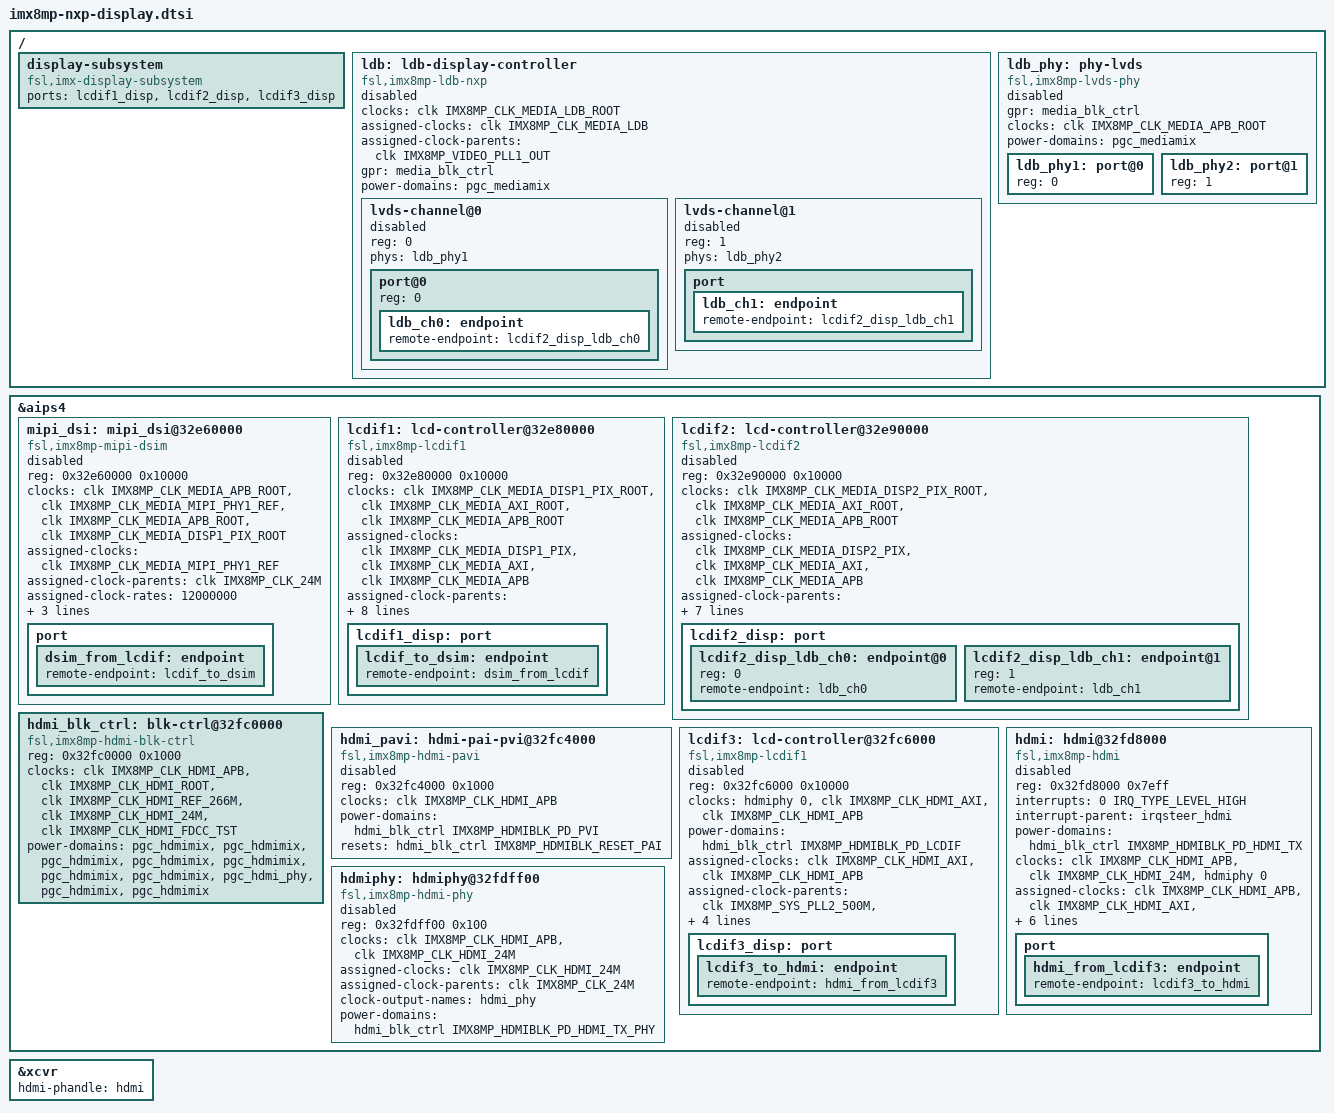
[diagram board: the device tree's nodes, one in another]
// SPDX-License-Identifier: (GPL-2.0+ OR MIT)
/*
 * Copyright 2025 NXP
 */

/delete-node/ &hdmi_blk_ctrl;
/delete-node/ &hdmi_pvi;
/delete-node/ &hdmi_tx;
/delete-node/ &hdmi_tx_phy;
/delete-node/ &lcdif1;
/delete-node/ &lcdif2;
/delete-node/ &lcdif3;
/delete-node/ &lvds_bridge;
/delete-node/ &mipi_dsi;

/ {
	display-subsystem {
		compatible = "fsl,imx-display-subsystem";
		ports = <&lcdif1_disp>, <&lcdif2_disp>, <&lcdif3_disp>;
	};

	ldb: ldb-display-controller {
		#address-cells = <1>;
		#size-cells = <0>;
		compatible = "fsl,imx8mp-ldb-nxp";
		clocks = <&clk IMX8MP_CLK_MEDIA_LDB_ROOT>;
		clock-names = "ldb";
		assigned-clocks = <&clk IMX8MP_CLK_MEDIA_LDB>;
		assigned-clock-parents = <&clk IMX8MP_VIDEO_PLL1_OUT>;
		gpr = <&media_blk_ctrl>;
		power-domains = <&pgc_mediamix>;
		status = "disabled";

		lvds-channel@0 {
			#address-cells = <1>;
			#size-cells = <0>;
			reg = <0>;
			phys = <&ldb_phy1>;
			phy-names = "ldb_phy";
			status = "disabled";

			port@0 {
				reg = <0>;

				ldb_ch0: endpoint {
					remote-endpoint = <&lcdif2_disp_ldb_ch0>;
				};
			};
		};

		lvds-channel@1 {
			reg = <1>;
			phys = <&ldb_phy2>;
			phy-names = "ldb_phy";
			status = "disabled";

			port {
				ldb_ch1: endpoint {
					remote-endpoint = <&lcdif2_disp_ldb_ch1>;
				};
			};
		};
	};

	ldb_phy: phy-lvds {
		compatible = "fsl,imx8mp-lvds-phy";
		#address-cells = <1>;
		#size-cells = <0>;
		gpr = <&media_blk_ctrl>;
		clocks = <&clk IMX8MP_CLK_MEDIA_APB_ROOT>;
		clock-names = "apb";
		power-domains = <&pgc_mediamix>;
		status = "disabled";

		ldb_phy1: port@0 {
			reg = <0>;
			#phy-cells = <0>;
		};

		ldb_phy2: port@1 {
			reg = <1>;
			#phy-cells = <0>;
		};
	};
};

&aips4 {
	mipi_dsi: mipi_dsi@32e60000 {
		#address-cells = <1>;
		#size-cells = <0>;
		compatible = "fsl,imx8mp-mipi-dsim";
		reg = <0x32e60000 0x10000>;
		clocks = <&clk IMX8MP_CLK_MEDIA_APB_ROOT>,
			 <&clk IMX8MP_CLK_MEDIA_MIPI_PHY1_REF>,
			 <&clk IMX8MP_CLK_MEDIA_APB_ROOT>,
			 <&clk IMX8MP_CLK_MEDIA_DISP1_PIX_ROOT>;
		clock-names = "cfg", "pll-ref", "apb-root", "pixel";
		assigned-clocks = <&clk IMX8MP_CLK_MEDIA_MIPI_PHY1_REF>;
		assigned-clock-parents = <&clk IMX8MP_CLK_24M>;
		assigned-clock-rates = <12000000>;
		interrupts = <GIC_SPI 18 IRQ_TYPE_LEVEL_HIGH>;
		power-domains = <&media_blk_ctrl IMX8MP_MEDIABLK_PD_MIPI_DSI_1>;
		status = "disabled";

		port {
			dsim_from_lcdif: endpoint {
				remote-endpoint = <&lcdif_to_dsim>;
			};
		};
	};

	lcdif1: lcd-controller@32e80000 {
		compatible = "fsl,imx8mp-lcdif1";
		reg = <0x32e80000 0x10000>;
		clocks = <&clk IMX8MP_CLK_MEDIA_DISP1_PIX_ROOT>,
			 <&clk IMX8MP_CLK_MEDIA_AXI_ROOT>,
			 <&clk IMX8MP_CLK_MEDIA_APB_ROOT>;
		clock-names = "pix", "disp-axi", "disp-apb";
		assigned-clocks = <&clk IMX8MP_CLK_MEDIA_DISP1_PIX>,
				  <&clk IMX8MP_CLK_MEDIA_AXI>,
				  <&clk IMX8MP_CLK_MEDIA_APB>;
		assigned-clock-parents = <&clk IMX8MP_VIDEO_PLL1_OUT>,
					 <&clk IMX8MP_SYS_PLL2_1000M>,
					 <&clk IMX8MP_SYS_PLL1_800M>;
		assigned-clock-rates = <0>, <500000000>, <200000000>;
		interrupts = <GIC_SPI 5 IRQ_TYPE_LEVEL_HIGH>;
		blk-ctl = <&media_blk_ctrl>;
		power-domains = <&media_blk_ctrl IMX8MP_MEDIABLK_PD_LCDIF_1>;
		status = "disabled";

		lcdif1_disp: port {
			lcdif_to_dsim: endpoint {
				remote-endpoint = <&dsim_from_lcdif>;
			};
		};
	};

	lcdif2: lcd-controller@32e90000 {
		compatible = "fsl,imx8mp-lcdif2";
		reg = <0x32e90000 0x10000>;
		clocks = <&clk IMX8MP_CLK_MEDIA_DISP2_PIX_ROOT>,
			 <&clk IMX8MP_CLK_MEDIA_AXI_ROOT>,
			 <&clk IMX8MP_CLK_MEDIA_APB_ROOT>;
		clock-names = "pix", "disp-axi", "disp-apb";
		assigned-clocks = <&clk IMX8MP_CLK_MEDIA_DISP2_PIX>,
				  <&clk IMX8MP_CLK_MEDIA_AXI>,
				  <&clk IMX8MP_CLK_MEDIA_APB>;
		assigned-clock-parents = <&clk IMX8MP_VIDEO_PLL1_OUT>,
					 <&clk IMX8MP_SYS_PLL2_1000M>,
					 <&clk IMX8MP_SYS_PLL1_800M>;
		assigned-clock-rates = <0>, <500000000>, <200000000>;
		interrupts = <GIC_SPI 6 IRQ_TYPE_LEVEL_HIGH>;
		power-domains = <&media_blk_ctrl IMX8MP_MEDIABLK_PD_LCDIF_2>;
		status = "disabled";

		lcdif2_disp: port {
			#address-cells = <1>;
			#size-cells = <0>;

			lcdif2_disp_ldb_ch0: endpoint@0 {
				reg = <0>;
				remote-endpoint = <&ldb_ch0>;
			};

			lcdif2_disp_ldb_ch1: endpoint@1 {
				reg = <1>;
				remote-endpoint = <&ldb_ch1>;
			};
		};
	};

	hdmi_blk_ctrl: blk-ctrl@32fc0000 {
		compatible = "fsl,imx8mp-hdmi-blk-ctrl", "syscon";
		reg = <0x32fc0000 0x1000>;
		clocks = <&clk IMX8MP_CLK_HDMI_APB>,
			 <&clk IMX8MP_CLK_HDMI_ROOT>,
			 <&clk IMX8MP_CLK_HDMI_REF_266M>,
			 <&clk IMX8MP_CLK_HDMI_24M>,
			 <&clk IMX8MP_CLK_HDMI_FDCC_TST>;
		clock-names = "apb", "axi", "ref_266m", "ref_24m", "fdcc";
		power-domains = <&pgc_hdmimix>, <&pgc_hdmimix>,
				<&pgc_hdmimix>, <&pgc_hdmimix>,
				<&pgc_hdmimix>, <&pgc_hdmimix>,
				<&pgc_hdmimix>, <&pgc_hdmi_phy>,
				<&pgc_hdmimix>, <&pgc_hdmimix>;
		power-domain-names = "bus", "irqsteer", "lcdif",
				     "pai", "pvi", "trng",
				     "hdmi-tx", "hdmi-tx-phy",
				     "hdcp", "hrv";
		#power-domain-cells = <1>;
		#reset-cells = <1>;
	};

	hdmi_pavi: hdmi-pai-pvi@32fc4000 {
		compatible = "fsl,imx8mp-hdmi-pavi";
		reg = <0x32fc4000 0x1000>;
		clocks = <&clk IMX8MP_CLK_HDMI_APB>;
		power-domains = <&hdmi_blk_ctrl IMX8MP_HDMIBLK_PD_PVI>;
		resets = <&hdmi_blk_ctrl IMX8MP_HDMIBLK_RESET_PAI>;
		reset-names = "pai_rst";
		status = "disabled";
	};

	lcdif3: lcd-controller@32fc6000 {
		compatible = "fsl,imx8mp-lcdif1";
		reg = <0x32fc6000 0x10000>;
		clocks = <&hdmiphy 0>,
				<&clk IMX8MP_CLK_HDMI_AXI>,
				<&clk IMX8MP_CLK_HDMI_APB>;
		clock-names = "pix", "disp-axi", "disp-apb";
		power-domains = <&hdmi_blk_ctrl IMX8MP_HDMIBLK_PD_LCDIF>;
		assigned-clocks =  <&clk IMX8MP_CLK_HDMI_AXI>,
						<&clk IMX8MP_CLK_HDMI_APB>;
		assigned-clock-parents = <&clk IMX8MP_SYS_PLL2_500M>,
					 <&clk IMX8MP_SYS_PLL1_133M>;
		assigned-clock-rates = <500000000>, <133000000>;
		interrupts = <8 IRQ_TYPE_LEVEL_HIGH>;
		interrupt-parent = <&irqsteer_hdmi>;
		status = "disabled";

		lcdif3_disp: port {
			lcdif3_to_hdmi: endpoint {
				remote-endpoint = <&hdmi_from_lcdif3>;
			};
		};
	};

	hdmi: hdmi@32fd8000 {
		compatible = "fsl,imx8mp-hdmi";
		reg = <0x32fd8000 0x7eff>;
		interrupts = <0 IRQ_TYPE_LEVEL_HIGH>;
		interrupt-parent = <&irqsteer_hdmi>;
		power-domains = <&hdmi_blk_ctrl IMX8MP_HDMIBLK_PD_HDMI_TX>;
		clocks = <&clk IMX8MP_CLK_HDMI_APB>,
				<&clk IMX8MP_CLK_HDMI_24M>,
				<&hdmiphy 0>;
		clock-names = "iahb", "isfr", "pix";
		assigned-clocks = <&clk IMX8MP_CLK_HDMI_APB>,
					<&clk IMX8MP_CLK_HDMI_AXI>,
					<&clk IMX8MP_CLK_HDMI_24M>;
		assigned-clock-parents = <&clk IMX8MP_SYS_PLL1_133M>,
					<&clk IMX8MP_SYS_PLL2_500M>,
					<&clk IMX8MP_CLK_24M>;
		assigned-clock-rates = <133000000>, <500000000>, <24000000>;
		status = "disabled";

		port {
			hdmi_from_lcdif3: endpoint {
				remote-endpoint = <&lcdif3_to_hdmi>;
			};
		};
	};

	hdmiphy: hdmiphy@32fdff00 {
		compatible = "fsl,imx8mp-hdmi-phy";
		reg = <0x32fdff00 0x100>;
		clocks = <&clk IMX8MP_CLK_HDMI_APB>,
			 <&clk IMX8MP_CLK_HDMI_24M>;
		clock-names = "apb", "ref";
		assigned-clocks = <&clk IMX8MP_CLK_HDMI_24M>;
		assigned-clock-parents = <&clk IMX8MP_CLK_24M>;
		#clock-cells = <1>;
		clock-output-names = "hdmi_phy";
		#phy-cells = <0>;
		power-domains = <&hdmi_blk_ctrl IMX8MP_HDMIBLK_PD_HDMI_TX_PHY>;
		status = "disabled";
	};
};

&xcvr {
	hdmi-phandle = <&hdmi>;
};
